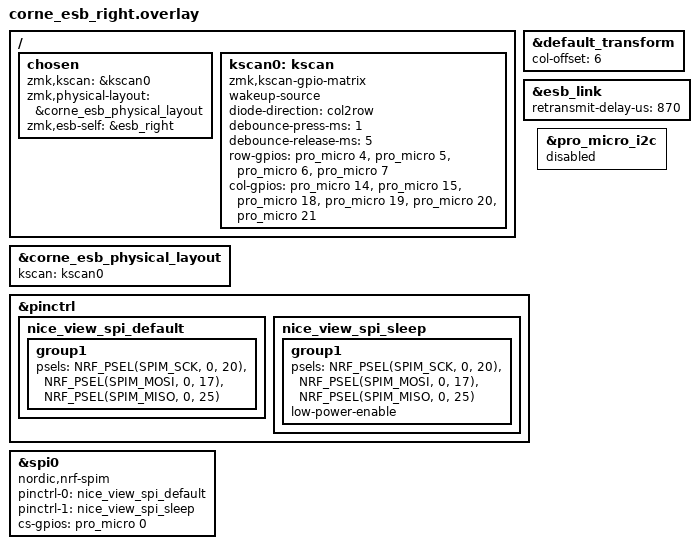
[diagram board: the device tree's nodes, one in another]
#include "corne_esb_matrix.dtsi"
#include "corne_esb_addr.dtsi"

/ {
    chosen {
        zmk,kscan = &kscan0;
        zmk,physical-layout = &corne_esb_physical_layout;
        zmk,esb-self = &esb_right;
    };

    /* Standard corne (crkbd) pinout (right half col order mirrors the left),
     * same debounce as the old corne-lp BLE config. */
    kscan0: kscan {
        compatible = "zmk,kscan-gpio-matrix";
        wakeup-source;
        diode-direction = "col2row";
        debounce-press-ms = <1>;
        debounce-release-ms = <5>;
        row-gpios
            = <&pro_micro 4 (GPIO_ACTIVE_HIGH | GPIO_PULL_DOWN)>
            , <&pro_micro 5 (GPIO_ACTIVE_HIGH | GPIO_PULL_DOWN)>
            , <&pro_micro 6 (GPIO_ACTIVE_HIGH | GPIO_PULL_DOWN)>
            , <&pro_micro 7 (GPIO_ACTIVE_HIGH | GPIO_PULL_DOWN)>
            ;
        col-gpios
            = <&pro_micro 14 GPIO_ACTIVE_HIGH>
            , <&pro_micro 15 GPIO_ACTIVE_HIGH>
            , <&pro_micro 18 GPIO_ACTIVE_HIGH>
            , <&pro_micro 19 GPIO_ACTIVE_HIGH>
            , <&pro_micro 20 GPIO_ACTIVE_HIGH>
            , <&pro_micro 21 GPIO_ACTIVE_HIGH>
            ;
    };
};

&default_transform {
    col-offset = <6>;
};

&corne_esb_physical_layout {
    kscan = <&kscan0>;
};

&esb_link {
    retransmit-delay-us = <870>;
};

/* nice!view display bus — driven on spi0 remapped to the pro_micro D3/D2 pads
 * (SCK P0.20, MOSI P0.17, MISO P0.25), CS on D0 (pro_micro 0). See
 * corne_esb_left.overlay for the full rationale (the board's pro_micro_spi is
 * spi1 on the wrong pads and leaves the panel showing "no-signal" static). */
&pinctrl {
    nice_view_spi_default: nice_view_spi_default {
        group1 {
            psels = <NRF_PSEL(SPIM_SCK, 0, 20)>,
                    <NRF_PSEL(SPIM_MOSI, 0, 17)>,
                    <NRF_PSEL(SPIM_MISO, 0, 25)>;
        };
    };
    nice_view_spi_sleep: nice_view_spi_sleep {
        group1 {
            psels = <NRF_PSEL(SPIM_SCK, 0, 20)>,
                    <NRF_PSEL(SPIM_MOSI, 0, 17)>,
                    <NRF_PSEL(SPIM_MISO, 0, 25)>;
            low-power-enable;
        };
    };
};

&pro_micro_i2c {
    status = "disabled";
};

nice_view_spi: &spi0 {
    compatible = "nordic,nrf-spim";
    status = "okay";
    pinctrl-0 = <&nice_view_spi_default>;
    pinctrl-1 = <&nice_view_spi_sleep>;
    pinctrl-names = "default", "sleep";
    cs-gpios = <&pro_micro 0 GPIO_ACTIVE_HIGH>;
};
